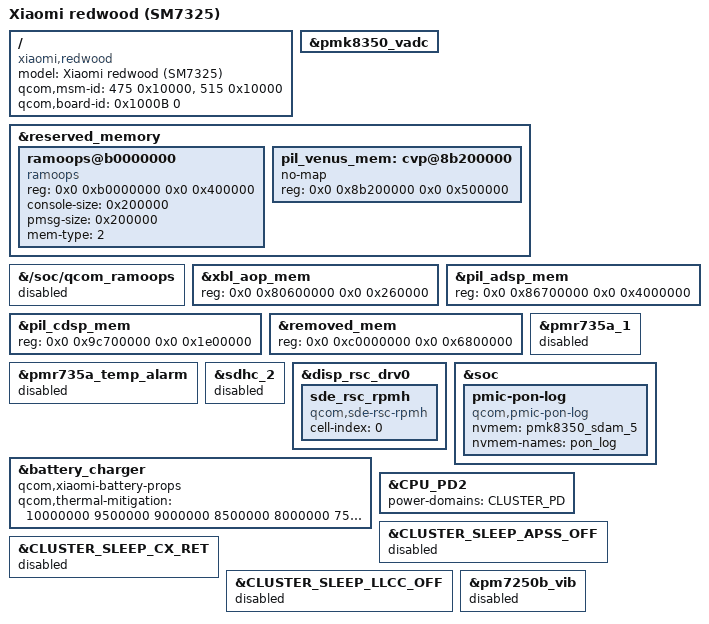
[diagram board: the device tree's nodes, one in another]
// SPDX-License-Identifier: BSD-3-Clause
/*
 * Xiaomi Redmi Note 12 Pro 5G / POCO X5 Pro 5G (redwood)
 *
 * Starts from Qualcomm's Yupik IDP board, which the 5.4 redwood device
 * tree was also built on.
 */

/dts-v1/;
/plugin/;

#include "yupik-idp.dtsi"
#include "display/redwood-sde-pinctrl.dtsi"
#include "display/redwood-sde.dtsi"
#include "display/redwood-sde-display.dtsi"
#include <dt-bindings/clock/qcom,gpucc-sc7280.h>
#include <dt-bindings/clock/qcom,aop-qmp.h>
#include "gpu/yupik-gpu.dtsi"
#include "gpu/yupik-gpu-pwrlevels.dtsi"
#include "redwood-touch.dtsi"
#include "redwood-wlan.dtsi"
#include "redwood-ipa.dtsi"
#include "redwood-fastrpc.dtsi"
#include "redwood-video.dtsi"
#include "redwood-bt.dtsi"
#include "redwood-camera.dtsi"
#include "redwood-fingerprint.dtsi"
#include "redwood-haptics.dtsi"
#include "redwood-ir.dtsi"
#include "redwood-touchfeature.dtsi"
#include "redwood-audio/yupik-audio.dtsi"
#include "redwood-audio/redwood-audio-overlay.dtsi"

/*
 * Not on redwood (the ADSP reads the battery), and 6.12's adc5 rejects
 * V_I_BAT_THERM, which failed the whole PMK8350 ADC: no board thermistors,
 * no ADC_TM, and both PMIC temp alarms stuck waiting for it.
 */
&pmk8350_vadc {
	/delete-node/ pm7325b_batt_therm;
};

/ {
	model = "Xiaomi redwood (SM7325)";
	compatible = "xiaomi,redwood", "qcom,yupik-idp", "qcom,yupik", "qcom,idp";
	qcom,msm-id = <475 0x10000>, <515 0x10000>;
	qcom,board-id = <0x1000B 0>;
};

/*
 * Keep the console log where the 5.4 kernel keeps it, so a 6.12 boot that
 * goes wrong can still be read from /sys/fs/pstore after booting 5.4.
 */
&reserved_memory {
	ramoops@b0000000 {
		compatible = "ramoops";
		reg = <0x0 0xb0000000 0x0 0x400000>;
		console-size = <0x200000>;
		pmsg-size = <0x200000>;
		mem-type = <2>;
	};
};

&{/soc/qcom_ramoops} {
	status = "disabled";
};

/*
 * redwood's firmware uses the older Yupik memory map, the one the 5.4
 * kernel describes: AOP starts at 0x80600000, the ADSP takes 64M, the CDSP
 * sits at 0x9c700000 and the CVP at 0x8b200000. Qualcomm's 6.12 map would
 * put the CDSP inside the ADSP's memory here and leave the CVP unreserved.
 */
&xbl_aop_mem {
	reg = <0x0 0x80600000 0x0 0x260000>;
};

&pil_adsp_mem {
	reg = <0x0 0x86700000 0x0 0x4000000>;
};

&pil_cdsp_mem {
	reg = <0x0 0x9c700000 0x0 0x1e00000>;
};

&removed_mem {
	reg = <0x0 0xc0000000 0x0 0x6800000>;
};

&reserved_memory {
	/* where the 5.4 PIL loads venus, which TZ expects */
	pil_venus_mem: cvp@8b200000 {
		no-map;
		reg = <0x0 0x8b200000 0x0 0x500000>;
	};
};

/* redwood has no PMR735A on the SPMI bus, and no SD card slot */
&pmr735a_1 {
	status = "disabled";
};

&pmr735a_temp_alarm {
	status = "disabled";
};

&sdhc_2 {
	status = "disabled";
};

/* The display RSC finds its RPMh controller through this */
&disp_rsc_drv0 {
	sde_rsc_rpmh {
		compatible = "qcom,sde-rsc-rpmh";
		cell-index = <0>;
	};
};

/*
 * redwood's charger firmware uses Xiaomi's battery property layout, and the
 * thermal levels are redwood's own from 10A (67W charging) down to 500mA.
 */
&battery_charger {
	qcom,xiaomi-battery-props;
	qcom,thermal-mitigation = <10000000 9500000 9000000 8500000 8000000
				   7500000 7000000 6500000 6000000 5500000
				   5000000 4500000 4000000 3500000 3000000
				   2500000 2000000 1500000 1000000 500000>;
};

/*
 * The PMIC keeps a log of every power on and off, with its reason, in
 * SDAM 5 of the PMK8350, as on lahaina; read it so a reset says why.
 */
&soc {
	pmic-pon-log {
		compatible = "qcom,pmic-pon-log";
		nvmem = <&pmk8350_sdam_5>;
		nvmem-names = "pon_log";
	};
};

/*
 * yupik.dtsi spells this "Power-domains", so CPU2 was never part of the
 * cluster domain: with OS-initiated PSCI the cluster could power down
 * while CPU2 was still running, and the phone reset every few minutes.
 * Set it here too, for a base DTB built before the fix.
 */
&CPU_PD2 {
	power-domains = <&CLUSTER_PD>;
};

/*
 * Entering any cluster idle state resets redwood on 6.12 with no log
 * (PMIC: PS_HOLD hard reset) a few minutes after boot, and the SMMU loses
 * its context bank state on the way (an IPA fault showed TTBR0 = 0).
 * With every deep idle state off, or the cluster states held off, it runs
 * for good. Keep the CPUs' own power collapse states and leave the
 * cluster out until whatever loses state there is found.
 */
&CLUSTER_SLEEP_APSS_OFF {
	status = "disabled";
};

&CLUSTER_SLEEP_CX_RET {
	status = "disabled";
};

&CLUSTER_SLEEP_LLCC_OFF {
	status = "disabled";
};

/*
 * redwood has no motor on the PMIC LDO vibrator output: the vibrator is the
 * AW86927 (redwood-haptics.dtsi). With this node probed it takes
 * /sys/class/leds/vibrator, the vibrator HAL drives it and nothing buzzes.
 */
&pm7250b_vib {
	status = "disabled";
};
